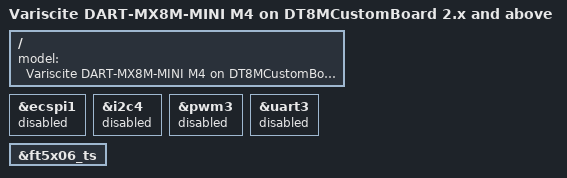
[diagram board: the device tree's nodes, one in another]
// SPDX-License-Identifier: (GPL-2.0+ OR MIT)
/*
 * Copyright 2019 NXP
 * Copyright 2019-2022 Variscite Ltd.
 */

#include "imx8mm-var-dart-dt8mcustomboard.dts"
#include "imx8mm-var-m4.dtsi"

/ {
	model = "Variscite DART-MX8M-MINI M4 on DT8MCustomBoard 2.x and above";
};

/*
 * ATTENTION: M4 may use the followings IPs:
 * ECSPI1, GPIO4, GPT1, I2C4, WDOG1, PWM3, SDMA1/3, UART3
 */

&ecspi1 {
	status = "disabled";
};

&i2c4 {
	status = "disabled";
};

&pwm3 {
	status = "disabled";
};

&uart3 {
	status = "disabled";
};

/*
 * For dt8mcustomboard >= 2.0, reset-gpios is connected to pca6408_2
 * on i2c4, which is disabled above for the m4 example
 */
&ft5x06_ts {
	/delete-property/reset-gpios;
};
